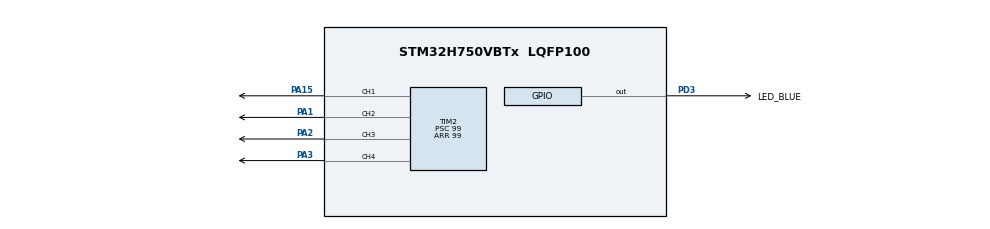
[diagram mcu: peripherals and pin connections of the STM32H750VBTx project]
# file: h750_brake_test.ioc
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Mcu.Family=STM32H7
Mcu.Name=STM32H750VBTx
Mcu.Package=LQFP100
NVIC.PriorityGroup=NVIC_PRIORITYGROUP_4
PA1.Signal=S_TIM2_CH2
PA13\ (JTMS/SWDIO).Mode=Serial_Wire
PA13\ (JTMS/SWDIO).Signal=DEBUG_JTMS-SWDIO
PA14\ (JTCK/SWCLK).Mode=Serial_Wire
PA14\ (JTCK/SWCLK).Signal=DEBUG_JTCK-SWCLK
PA15\ (JTDI).Signal=S_TIM2_CH1_ETR
PA2.Signal=S_TIM2_CH3
PA3.Signal=S_TIM2_CH4
PC14-OSC32_IN\ (OSC32_IN).Mode=LSE-External-Oscillator
PC14-OSC32_IN\ (OSC32_IN).Signal=RCC_OSC32_IN
PC15-OSC32_OUT\ (OSC32_OUT).Mode=LSE-External-Oscillator
PC15-OSC32_OUT\ (OSC32_OUT).Signal=RCC_OSC32_OUT
PD3.GPIO_Label=LED_BLUE
PD3.Signal=GPIO_Output
PH0-OSC_IN\ (PH0).Mode=HSE-External-Oscillator
PH0-OSC_IN\ (PH0).Signal=RCC_OSC_IN
PH1-OSC_OUT\ (PH1).Mode=HSE-External-Oscillator
PH1-OSC_OUT\ (PH1).Signal=RCC_OSC_OUT
ProjectManager.HeapSize=0x200
ProjectManager.StackSize=0x400
ProjectManager.TargetToolchain=STM32CubeIDE
RCC.ADCFreq_Value=50390625
RCC.APB1Freq_Value=50000000
RCC.APB2Freq_Value=50000000
RCC.APB3Freq_Value=50000000
RCC.APB4Freq_Value=50000000
RCC.CortexFreq_Value=400000000
RCC.D1PPRE=RCC_APB3_DIV2
RCC.D2PPRE1=RCC_APB1_DIV2
RCC.D2PPRE2=RCC_APB2_DIV2
RCC.D3PPRE=RCC_APB4_DIV2
RCC.DIVM1=5
RCC.DIVN1=160
RCC.HCLKFreq_Value=100000000
RCC.HPRE=RCC_HCLK_DIV4
RCC.PLLSourceVirtual=RCC_PLLSOURCE_HSE
RCC.SYSCLKFreq_VALUE=400000000
RCC.SYSCLKSource=RCC_SYSCLKSOURCE_PLLCLK
RCC.USBFreq_Value=400000000
SH.S_TIM2_CH1_ETR.0=TIM2_CH1,PWM Generation1 CH1
SH.S_TIM2_CH2.0=TIM2_CH2,PWM Generation2 CH2
SH.S_TIM2_CH3.0=TIM2_CH3,PWM Generation3 CH3
SH.S_TIM2_CH4.0=TIM2_CH4,PWM Generation4 CH4
TIM2.AutoReloadPreload=TIM_AUTORELOAD_PRELOAD_ENABLE
TIM2.Channel-PWM\ Generation1\ CH1=TIM_CHANNEL_1
TIM2.Channel-PWM\ Generation2\ CH2=TIM_CHANNEL_2
TIM2.Channel-PWM\ Generation3\ CH3=TIM_CHANNEL_3
TIM2.Channel-PWM\ Generation4\ CH4=TIM_CHANNEL_4
TIM2.Period=99
TIM2.Prescaler=99
VP_TIM2_VS_ClockSourceINT.Mode=Internal
board=custom

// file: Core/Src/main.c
/* USER CODE BEGIN Header */
/**
  ******************************************************************************
  * @file           : main.c
  * @brief          : Main program body
  ******************************************************************************
  * @attention
  *
  * Copyright (c) 2023 STMicroelectronics.
  * All rights reserved.
  *
  * This software is licensed under terms that can be found in the LICENSE file
  * in the root directory of this software component.
  * If no LICENSE file comes with this software, it is provided AS-IS.
  *
  ******************************************************************************
  */
/* USER CODE END Header */
#include "main.h"

TIM_HandleTypeDef htim2;

void SystemClock_Config(void);
static void MX_GPIO_Init(void);
static void MX_TIM2_Init(void);

int main(void)
{

  /* MCU Configuration--------------------------------------------------------*/

  /* Reset of all peripherals, Initializes the Flash interface and the Systick. */
  HAL_Init();

  /* Configure the system clock */
  SystemClock_Config();

  /* Initialize all configured peripherals */
  MX_GPIO_Init();
  MX_TIM2_Init();
  /* USER CODE BEGIN 2 */

  TIM2->CCR1=20;
  TIM2->CCR2=40;
  TIM2->CCR3=60;
  TIM2->CCR4=80;

  HAL_TIM_PWM_Start(&htim2, TIM_CHANNEL_1);
  HAL_TIM_PWM_Start(&htim2, TIM_CHANNEL_2);
  HAL_TIM_PWM_Start(&htim2, TIM_CHANNEL_3);
  HAL_TIM_PWM_Start(&htim2, TIM_CHANNEL_4);

  /* USER CODE END 2 */

  /* Infinite loop */
  while (1)
  {
	  HAL_GPIO_TogglePin(LED_BLUE_GPIO_Port, LED_BLUE_Pin);
	  HAL_Delay(500);

  }
}

void SystemClock_Config(void)
{
  RCC_OscInitTypeDef RCC_OscInitStruct = {0};
  RCC_ClkInitTypeDef RCC_ClkInitStruct = {0};

  /** Supply configuration update enable
  */
  HAL_PWREx_ConfigSupply(PWR_LDO_SUPPLY);

  /** Configure the main internal regulator output voltage
  */
  __HAL_PWR_VOLTAGESCALING_CONFIG(PWR_REGULATOR_VOLTAGE_SCALE1);

  while(!__HAL_PWR_GET_FLAG(PWR_FLAG_VOSRDY)) {}

  /** Initializes the RCC Oscillators according to the specified parameters
  * in the RCC_OscInitTypeDef structure.
  */
  RCC_OscInitStruct.OscillatorType = RCC_OSCILLATORTYPE_HSE;
  RCC_OscInitStruct.HSEState = RCC_HSE_ON;
  RCC_OscInitStruct.PLL.PLLState = RCC_PLL_ON;
  RCC_OscInitStruct.PLL.PLLSource = RCC_PLLSOURCE_HSE;
  RCC_OscInitStruct.PLL.PLLM = 5;
  RCC_OscInitStruct.PLL.PLLN = 160;
  RCC_OscInitStruct.PLL.PLLP = 2;
  RCC_OscInitStruct.PLL.PLLQ = 2;
  RCC_OscInitStruct.PLL.PLLR = 2;
  RCC_OscInitStruct.PLL.PLLRGE = RCC_PLL1VCIRANGE_2;
  RCC_OscInitStruct.PLL.PLLVCOSEL = RCC_PLL1VCOWIDE;
  RCC_OscInitStruct.PLL.PLLFRACN = 0;
  if (HAL_RCC_OscConfig(&RCC_OscInitStruct) != HAL_OK)
  {
    Error_Handler();
  }

  /** Initializes the CPU, AHB and APB buses clocks
  */
  RCC_ClkInitStruct.ClockType = RCC_CLOCKTYPE_HCLK|RCC_CLOCKTYPE_SYSCLK
                              |RCC_CLOCKTYPE_PCLK1|RCC_CLOCKTYPE_PCLK2
                              |RCC_CLOCKTYPE_D3PCLK1|RCC_CLOCKTYPE_D1PCLK1;
  RCC_ClkInitStruct.SYSCLKSource = RCC_SYSCLKSOURCE_PLLCLK;
  RCC_ClkInitStruct.SYSCLKDivider = RCC_SYSCLK_DIV1;
  RCC_ClkInitStruct.AHBCLKDivider = RCC_HCLK_DIV4;
  RCC_ClkInitStruct.APB3CLKDivider = RCC_APB3_DIV2;
  RCC_ClkInitStruct.APB1CLKDivider = RCC_APB1_DIV2;
  RCC_ClkInitStruct.APB2CLKDivider = RCC_APB2_DIV2;
  RCC_ClkInitStruct.APB4CLKDivider = RCC_APB4_DIV2;

  if (HAL_RCC_ClockConfig(&RCC_ClkInitStruct, FLASH_LATENCY_1) != HAL_OK)
  {
    Error_Handler();
  }
}

static void MX_TIM2_Init(void)
{

  TIM_ClockConfigTypeDef sClockSourceConfig = {0};
  TIM_MasterConfigTypeDef sMasterConfig = {0};
  TIM_OC_InitTypeDef sConfigOC = {0};

  htim2.Instance = TIM2;
  htim2.Init.Prescaler = 99;
  htim2.Init.CounterMode = TIM_COUNTERMODE_UP;
  htim2.Init.Period = 99;
  htim2.Init.ClockDivision = TIM_CLOCKDIVISION_DIV1;
  htim2.Init.AutoReloadPreload = TIM_AUTORELOAD_PRELOAD_ENABLE;
  if (HAL_TIM_Base_Init(&htim2) != HAL_OK)
  {
    Error_Handler();
  }
  sClockSourceConfig.ClockSource = TIM_CLOCKSOURCE_INTERNAL;
  if (HAL_TIM_ConfigClockSource(&htim2, &sClockSourceConfig) != HAL_OK)
  {
    Error_Handler();
  }
  if (HAL_TIM_PWM_Init(&htim2) != HAL_OK)
  {
    Error_Handler();
  }
  sMasterConfig.MasterOutputTrigger = TIM_TRGO_RESET;
  sMasterConfig.MasterSlaveMode = TIM_MASTERSLAVEMODE_DISABLE;
  if (HAL_TIMEx_MasterConfigSynchronization(&htim2, &sMasterConfig) != HAL_OK)
  {
    Error_Handler();
  }
  sConfigOC.OCMode = TIM_OCMODE_PWM1;
  sConfigOC.Pulse = 0;
  sConfigOC.OCPolarity = TIM_OCPOLARITY_HIGH;
  sConfigOC.OCFastMode = TIM_OCFAST_DISABLE;
  if (HAL_TIM_PWM_ConfigChannel(&htim2, &sConfigOC, TIM_CHANNEL_1) != HAL_OK)
  {
    Error_Handler();
  }
  if (HAL_TIM_PWM_ConfigChannel(&htim2, &sConfigOC, TIM_CHANNEL_2) != HAL_OK)
  {
    Error_Handler();
  }
  if (HAL_TIM_PWM_ConfigChannel(&htim2, &sConfigOC, TIM_CHANNEL_3) != HAL_OK)
  {
    Error_Handler();
  }
  if (HAL_TIM_PWM_ConfigChannel(&htim2, &sConfigOC, TIM_CHANNEL_4) != HAL_OK)
  {
    Error_Handler();
  }
  HAL_TIM_MspPostInit(&htim2);

}

static void MX_GPIO_Init(void)
{
  GPIO_InitTypeDef GPIO_InitStruct = {0};

  /* GPIO Ports Clock Enable */
  __HAL_RCC_GPIOC_CLK_ENABLE();
  __HAL_RCC_GPIOH_CLK_ENABLE();
  __HAL_RCC_GPIOA_CLK_ENABLE();
  __HAL_RCC_GPIOD_CLK_ENABLE();

  /*Configure GPIO pin Output Level */
  HAL_GPIO_WritePin(LED_BLUE_GPIO_Port, LED_BLUE_Pin, GPIO_PIN_RESET);

  /*Configure GPIO pin : LED_BLUE_Pin */
  GPIO_InitStruct.Pin = LED_BLUE_Pin;
  GPIO_InitStruct.Mode = GPIO_MODE_OUTPUT_PP;
  GPIO_InitStruct.Pull = GPIO_NOPULL;
  GPIO_InitStruct.Speed = GPIO_SPEED_FREQ_LOW;
  HAL_GPIO_Init(LED_BLUE_GPIO_Port, &GPIO_InitStruct);

}

void Error_Handler(void)
{
  __disable_irq();
  while (1)
  {
  }
}
